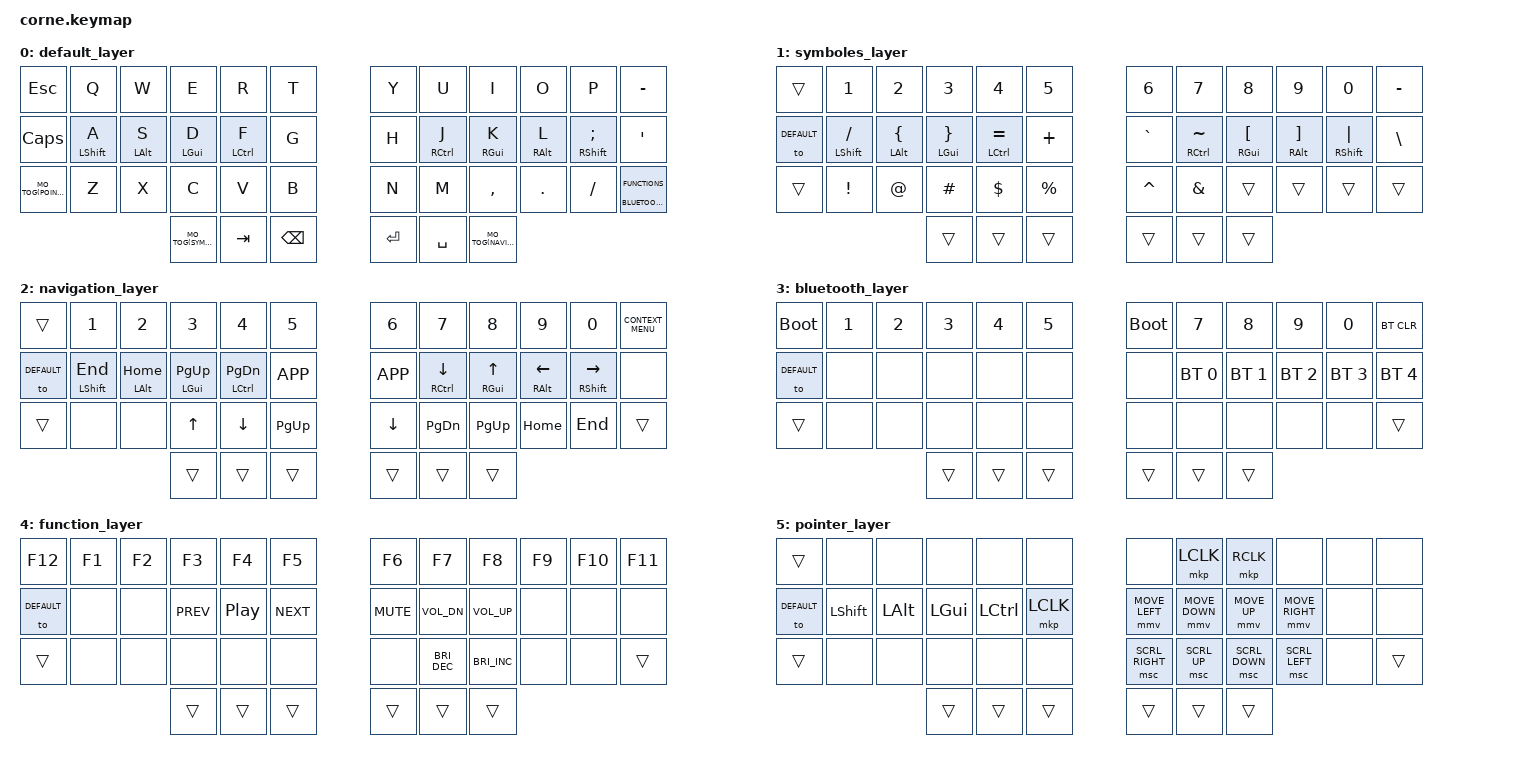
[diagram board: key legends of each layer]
/*
 * Copyright (c) 2020 The ZMK Contributors
 *
 * SPDX-License-Identifier: MIT
 */

#include <behaviors.dtsi>
#include <dt-bindings/zmk/keys.h>
#include <dt-bindings/zmk/bt.h>

// mouse emulation
#define ZMK_POINTING_DEFAULT_MOVE_VAL 1500  // default: 600
#define ZMK_POINTING_DEFAULT_SCRL_VAL 20    // default: 10
#include <dt-bindings/zmk/pointing.h>

#define DEFAULT 0
#define SYMBOLS 1
#define NAVIGATION 2
#define BLUETOOTH 3
#define FUNCTIONS 4
#define POINTER 5

// Macro to apply momentary-layer-on-hold/toggle-layer-on-tap to a specific layer
#define MO_TOG(layer) &mo_tog layer layer


/ {
        behaviors {
                bhm: balanced_homerow_mods {
                        compatible = "zmk,behavior-hold-tap";
                        label = "HOMEROW_MODS";
                        #binding-cells = <2>;
                        tapping-term-ms = <200>;    // <---[[moderate duration]]
                        quick-tap-ms = <400>;
                        flavor = "balanced";
                        bindings = <&kp>, <&kp>;
                };

                mo_tog: behavior_mo_tog {
                        compatible = "zmk,behavior-hold-tap";
                        label = "mo_tog";
                        #binding-cells = <2>;
                        flavor = "hold-preferred";
                        tapping-term-ms = <200>;
                        bindings = <&mo>, <&tog>;
                };

                kp_mo: balanced_kp_mods {
                        compatible = "zmk,behavior-hold-tap";
                        label = "KEYPRESS_MOMENTARY_LAYER";
                        #binding-cells = <2>;
                        tapping-term-ms = <200>;    // <---[[moderate duration]]
                        quick-tap-ms = <400>;
                        flavor = "balanced";
                        bindings = <&kp>, <&mo>;
                };

        };

        // conditional_layers {
                // compatible = "zmk,conditional-layers";
                // tri_layer {
                // if-layers = <SYMBOLS NAVIGATION>;
                // then-layer = <BLUETOOTH>;
                // };
        // };

        keymap {
                compatible = "zmk,keymap";

                default_layer {
// -----------------------------------------------------------------------------------------
// |  ESC |  Q  |  W  |  E  |  R  |  T  |   |  Y  |  U   |  I  |  O  |  P  | MINUS |
// | CAPS |  LS/A  |  LA/S  |  LG/D  |  LC/F  |  G  |   |  H  |  RC/J   |  RG/K  |  RA/L  |  RS/;  |  '   |
// | PTR|  Z  |  X  |  C  |  V  |  B  |   |  N  |  M   |  ,  |  .  |  /  | BLT/FUNC  |
//                    | SYM | TAB | BKSP |   | ENT | SPACE  | NAV |
                        bindings = <
   &kp ESC   &kp Q &kp W &kp E &kp R &kp T   &kp Y &kp U  &kp I     &kp O   &kp P    &kp MINUS
   &kp CAPS &bhm LSHIFT A &bhm LALT S &bhm LGUI D &bhm LCTRL F &kp G   &kp H &bhm RCTRL J  &bhm RGUI K   &bhm RALT L   &bhm RSHIFT SEMI &kp SQT
   MO_TOG(POINTER) &kp Z &kp X &kp C &kp V &kp B   &kp N &kp M  &kp COMMA &kp DOT &kp FSLH &mo_tog BLUETOOTH FUNCTIONS
                  MO_TOG(SYMBOLS)  &kp TAB &kp BSPC    &kp RET  &kp SPACE MO_TOG(NAVIGATION)
                        >;
                };

                symboles_layer {
// -----------------------------------------------------------------------------------------
// |      |  1  |  2  |  3  |  4  |  5  |   |  6  |  7  |  8  |  9  |  0  | MINUS |
// | DFT  | LS//|Lå/{ |LG/} |LC/= |  +  |   |  `  |RC/~ |RG/[ |RA/] | RS/PIPE|  BSLH |
// |      |  !  |  @  |  #  |  $  |  %  |   |  ^  |  &  |     |     |     |       |
//                    |     |     |     |   |     |     |     |
                        bindings = <
   &trans       &kp N1  &kp N2  &kp N3     &kp N4       &kp N5     &kp N6   &kp N7   &kp N8 &kp N9    &kp N0 &kp MINUS
   &to DEFAULT  &bhm LSHIFT SLASH &bhm LALT LBRC &bhm LGUI RBRC  &bhm LCTRL EQUAL    &kp PLUS   &kp GRAVE   &bhm RCTRL TILDE   &bhm RGUI LBKT &bhm RALT RBKT &bhm RSHIFT PIPE &kp BSLH
   &trans       &kp EXCL &kp AT &kp HASH &kp DLLR &kp PRCNT   &kp CARET &kp AMPS  &trans &trans &trans &trans
                &trans       &trans       &trans         &trans   &trans   &trans
                        >;
                };

                navigation_layer {
// -----------------------------------------------------------------------------------------
// |      |  1  |  2  |  3  |  4  |  5  |   |  6  |  7  |  8  |  9  |  0  | CONTEXT MENU |
// | DFT  | LS/END|Lå/HOME |LG/PGUP |LC/PGDN | APPL |   | APPL |RC/DOWN |RG/UP |RA/LEFT | RS/RIGHT|  none |
// |      | none | none | UP | DOWN | PGUP |   | DOWN | PGDN | PGUP | HOME | END |       |
//                    |     |     |     |   |     |     |     |
                        bindings = <
   &trans       &kp N1  &kp N2  &kp N3     &kp N4       &kp N5     &kp N6   &kp N7   &kp N8 &kp N9    &kp N0 &kp K_CONTEXT_MENU
   &to DEFAULT  &bhm LSHIFT END &bhm LALT HOME &bhm LGUI PG_UP &bhm LCTRL PG_DN  &kp K_APP      &kp K_APP &bhm RCTRL DOWN &bhm RGUI UP &bhm RALT LEFT &bhm RSHIFT RIGHT &none
   &trans       &none &none &kp UP &kp DOWN &kp PG_UP      &kp DOWN &kp PG_DN  &kp PG_UP &kp HOME &kp END &trans
                &trans       &trans       &trans         &trans   &trans   &trans
                        >;
                };

                bluetooth_layer {
// -----------------------------------------------------------------------------------------
// | BOOTLOADER |  1  |   2 |  3  |  4  |  5  |   | BOOTLOADER  |  7  |  8  |  9   |  0  | BTCLR  |
// | DFT        |     |     |     |     |     |   |             | BT1 | BT2 |  BT3 | BT4 |  BT5   |
// |            |     |     |     |     |     |   |             |     |     |      |     |        |
//                    |     |     |     |   |     |     |     |
                        bindings = <
   &bootloader    &kp N1       &kp N2       &kp N3       &kp N4       &kp N5    &bootloader   &kp N7        &kp N8        &kp N9        &kp N0        &bt BT_CLR
   &to DEFAULT    &none        &none        &none        &none        &none     &none         &bt BT_SEL 0  &bt BT_SEL 1  &bt BT_SEL 2  &bt BT_SEL 3  &bt BT_SEL 4
   &trans         &none        &none        &none        &none        &none     &none         &none         &none         &none         &none         &trans
                          	        &trans     &trans       &trans      &trans  &trans   &trans
                        >;
                };

                function_layer {
// -----------------------------------------------------------------------------------------
// |  F12 |  F1  |  F2  |  F3  |  F4  |  F5  |   |  F6  |  F7     |  F8    |  F9  |  F10  | F11   |
// |  DFT | none | none | PREV | PAUSE| NEXT |   | MUTE | VO_DOWN |  VO_UP | none | none  |  none |
// |      | none | none | none | none | none |   | none | DEC_BRI  | INC_BRI | none | none |      |
//                    |     |     |     |   |     |     |     |
                        bindings = <
   &kp F12     &kp F1    &kp F2    &kp F3   &kp F4   &kp F5    &kp F6  &kp F7   &kp F8 &kp F9   &kp F10 &kp F11
   &to DEFAULT &none &none &kp C_PREV &kp C_PLAY_PAUSE &kp C_NEXT   &kp K_MUTE &kp C_VOL_DN &kp C_VOL_UP &none &none &none
   &trans      &none    &none    &none    &none  &none         &none   &kp C_BRI_DEC   &kp C_BRI_INC &none &none &trans
                          	        &trans     &trans       &trans      &trans  &trans   &trans
                        >;
                };

                pointer_layer {
// -----------------------------------------------------------------------------------------
// |      |      |      |      |     |        |   |  none       |  LClick    | RClick      |             |    |  |
// | DFT  | LS   | LA   | LG   | LC  | LClick |   | MOVE_LEFT   | MOVE_DOWN  |  MOVE_UP    | MOVE_RIGHT  | none |  none |
// |      | none | none | none | none | none  |   | SCRL_RIGHTw | SCRL_UP    |   SCRL_DOWN | SCRL_LEFT   | none |      |
//                    |     |     |     |   |     |     |     |
                        bindings = <
   &trans        &none       &none      &none      &none       &none            &none              &mkp LCLK           &mkp RCLK         &none            &none &none
   &to DEFAULT   &kp LSHIFT  &kp LALT   &kp LGUI   &kp LCTRL   &mkp LCLK        &mmv MOVE_LEFT     &mmv MOVE_DOWN      &mmv MOVE_UP      &mmv MOVE_RIGHT  &none &none
   &trans        &none       &none      &none      &none       &none            &msc SCRL_RIGHT    &msc SCRL_UP        &msc SCRL_DOWN    &msc SCRL_LEFT  &none &trans
                          	        &trans     &trans       &trans      &trans  &trans   &trans
                        >;
                };




// these 2 are global

        };
};
